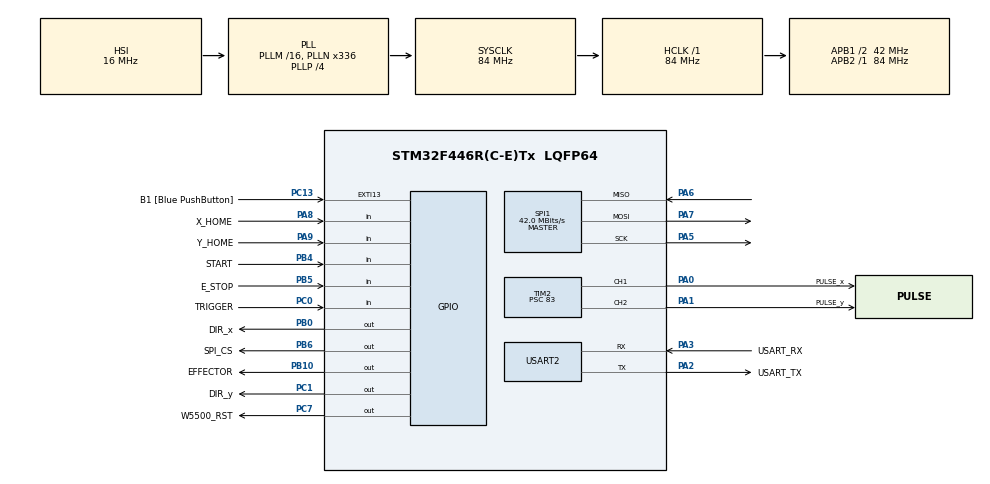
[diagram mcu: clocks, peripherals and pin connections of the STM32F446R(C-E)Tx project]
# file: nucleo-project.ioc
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Mcu.Family=STM32F4
Mcu.Name=STM32F446R(C-E)Tx
Mcu.Package=LQFP64
NVIC.PriorityGroup=NVIC_PRIORITYGROUP_4
NVIC.TIM2_IRQn=true\:0\:0\:false\:false\:true\:true\:true\:true
PA0-WKUP.GPIO_Label=PULSE_x
PA0-WKUP.GPIO_ModeDefaultPP=GPIO_MODE_AF_OD
PA0-WKUP.Signal=S_TIM2_CH1_ETR
PA1.GPIO_Label=PULSE_y
PA1.GPIO_ModeDefaultPP=GPIO_MODE_AF_OD
PA1.Signal=S_TIM2_CH2
PA13.GPIO_Label=TMS
PA13.Mode=Serial_Wire
PA13.Signal=SYS_JTMS-SWDIO
PA14.GPIO_Label=TCK
PA14.Mode=Serial_Wire
PA14.Signal=SYS_JTCK-SWCLK
PA2.GPIO_Label=USART_TX
PA2.Mode=Asynchronous
PA2.Signal=USART2_TX
PA3.GPIO_Label=USART_RX
PA3.Mode=Asynchronous
PA3.Signal=USART2_RX
PA5.Mode=Full_Duplex_Master
PA5.Signal=SPI1_SCK
PA6.Mode=Full_Duplex_Master
PA6.Signal=SPI1_MISO
PA7.Mode=Full_Duplex_Master
PA7.Signal=SPI1_MOSI
PA8.GPIO_Label=X_HOME
PA8.GPIO_PuPd=GPIO_PULLUP
PA8.Signal=GPIO_Input
PA9.GPIO_Label=Y_HOME
PA9.GPIO_PuPd=GPIO_PULLUP
PA9.Signal=GPIO_Input
PB0.GPIO_Label=DIR_x
PB0.GPIO_ModeDefaultOutputPP=GPIO_MODE_OUTPUT_OD
PB0.PinState=GPIO_PIN_SET
PB0.Signal=GPIO_Output
PB10.GPIO_Label=EFFECTOR
PB10.GPIO_ModeDefaultOutputPP=GPIO_MODE_OUTPUT_OD
PB10.GPIO_PuPd=GPIO_NOPULL
PB10.Signal=GPIO_Output
PB3.GPIO_Label=SWO
PB3.Signal=SYS_JTDO-SWO
PB4.GPIO_Label=START
PB4.GPIO_PuPd=GPIO_PULLUP
PB4.Signal=GPIO_Input
PB5.GPIO_Label=E_STOP
PB5.GPIO_PuPd=GPIO_PULLDOWN
PB5.Signal=GPIO_Input
PB6.GPIO_Label=SPI_CS
PB6.PinState=GPIO_PIN_SET
PB6.Signal=GPIO_Output
PC0.GPIO_Label=TRIGGER
PC0.GPIO_PuPd=GPIO_PULLUP
PC0.Signal=GPIO_Input
PC1.GPIO_Label=DIR_y
PC1.GPIO_ModeDefaultOutputPP=GPIO_MODE_OUTPUT_OD
PC1.PinState=GPIO_PIN_SET
PC1.Signal=GPIO_Output
PC13.GPIO_Label=B1 [Blue PushButton]
PC13.GPIO_ModeDefaultEXTI=GPIO_MODE_IT_FALLING
PC13.Signal=GPXTI13
PC14-OSC32_IN.Mode=LSE-External-Oscillator
PC14-OSC32_IN.Signal=RCC_OSC32_IN
PC15-OSC32_OUT.Mode=LSE-External-Oscillator
PC15-OSC32_OUT.Signal=RCC_OSC32_OUT
PC7.GPIO_Label=W5500_RST
PC7.PinState=GPIO_PIN_SET
PC7.Signal=GPIO_Output
PH0-OSC_IN.Mode=HSE-External-Oscillator
PH0-OSC_IN.Signal=RCC_OSC_IN
PH1-OSC_OUT.Mode=HSE-External-Oscillator
PH1-OSC_OUT.Signal=RCC_OSC_OUT
ProjectManager.HeapSize=0x200
ProjectManager.StackSize=0x400
ProjectManager.TargetToolchain=CMake
RCC.48MHZClocksFreq_Value=84000000
RCC.AHBFreq_Value=84000000
RCC.APB1CLKDivider=RCC_HCLK_DIV2
RCC.APB1Freq_Value=42000000
RCC.APB1TimFreq_Value=84000000
RCC.APB2Freq_Value=84000000
RCC.APB2TimFreq_Value=84000000
RCC.CortexFreq_Value=84000000
RCC.FLatency-AdvancedSettings=FLASH_LATENCY_2
RCC.HCLKFreq_Value=84000000
RCC.HSE_VALUE=8000000
RCC.HSI_VALUE=16000000
RCC.PLLN=336
RCC.PLLP=RCC_PLLP_DIV4
RCC.SYSCLKFreq_VALUE=84000000
RCC.SYSCLKSource=RCC_SYSCLKSOURCE_PLLCLK
RCC.USBFreq_Value=168000000
RCC.VCOOutputFreq_Value=336000000
SH.S_TIM2_CH1_ETR.0=TIM2_CH1,Output Compare1 CH1
SH.S_TIM2_CH2.0=TIM2_CH2,Output Compare2 CH2
SPI1.BaudRatePrescaler=SPI_BAUDRATEPRESCALER_2
SPI1.CLKPolarity=SPI_POLARITY_LOW
SPI1.CalculateBaudRate=42.0 MBits/s
SPI1.Direction=SPI_DIRECTION_2LINES
SPI1.Mode=SPI_MODE_MASTER
SPI1.VirtualType=VM_MASTER
TIM2.Channel-Output\ Compare1\ CH1=TIM_CHANNEL_1
TIM2.Channel-Output\ Compare2\ CH2=TIM_CHANNEL_2
TIM2.OCMode_1=TIM_OCMODE_TOGGLE
TIM2.OCMode_2=TIM_OCMODE_TOGGLE
TIM2.OCPolarity_1=TIM_OCPOLARITY_LOW
TIM2.OCPolarity_2=TIM_OCPOLARITY_LOW
TIM2.Prescaler=83
USART2.VirtualMode=VM_ASYNC
VP_TIM2_VS_ClockSourceINT.Mode=Internal
board=NUCLEO-F446RE

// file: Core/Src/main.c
/* USER CODE BEGIN Header */
/**
 ******************************************************************************
 * @file           : main.c
 * @brief          : Main program body
 ******************************************************************************
 * @attention
 *
 * Copyright (c) 2026 STMicroelectronics.
 * All rights reserved.
 *
 * This software is licensed under terms that can be found in the LICENSE file
 * in the root directory of this software component.
 * If no LICENSE file comes with this software, it is provided AS-IS.
 *
 ******************************************************************************
 */
/* USER CODE END Header */
#include "main.h"

/* USER CODE BEGIN Includes */

#include "entrypoint.hpp"

#include "stm32f4xx_hal.h"
#include "stm32f4xx_hal_def.h"
#include "stm32f4xx_hal_uart.h"

#include <stdint.h>

/* USER CODE END Includes */

SPI_HandleTypeDef hspi1;

TIM_HandleTypeDef htim2;

UART_HandleTypeDef huart2;

void SystemClock_Config(void);
static void MX_GPIO_Init(void);
static void MX_USART2_UART_Init(void);
static void MX_SPI1_Init(void);
static void MX_TIM2_Init(void);

/* USER CODE BEGIN 0 */

int __io_putchar(int ch)
{
    HAL_UART_Transmit(&huart2, (uint8_t *)&ch, 1, HAL_MAX_DELAY);
    return ch;
}

/* USER CODE END 0 */

int main(void)
{

  /* MCU Configuration--------------------------------------------------------*/

  /* Reset of all peripherals, Initializes the Flash interface and the Systick. */
  HAL_Init();

  /* Configure the system clock */
  SystemClock_Config();

  /* Initialize all configured peripherals */
  MX_GPIO_Init();
  MX_USART2_UART_Init();
  MX_SPI1_Init();
  MX_TIM2_Init();
  /* USER CODE BEGIN 2 */

    setup();

  /* USER CODE END 2 */

  /* Infinite loop */
  /* USER CODE BEGIN WHILE */

    while (1)
    {
        loop();

    /* USER CODE END WHILE */

    }
}

void SystemClock_Config(void)
{
  RCC_OscInitTypeDef RCC_OscInitStruct = {0};
  RCC_ClkInitTypeDef RCC_ClkInitStruct = {0};

  /** Configure the main internal regulator output voltage
  */
  __HAL_RCC_PWR_CLK_ENABLE();
  __HAL_PWR_VOLTAGESCALING_CONFIG(PWR_REGULATOR_VOLTAGE_SCALE3);

  /** Initializes the RCC Oscillators according to the specified parameters
  * in the RCC_OscInitTypeDef structure.
  */
  RCC_OscInitStruct.OscillatorType = RCC_OSCILLATORTYPE_HSI;
  RCC_OscInitStruct.HSIState = RCC_HSI_ON;
  RCC_OscInitStruct.HSICalibrationValue = RCC_HSICALIBRATION_DEFAULT;
  RCC_OscInitStruct.PLL.PLLState = RCC_PLL_ON;
  RCC_OscInitStruct.PLL.PLLSource = RCC_PLLSOURCE_HSI;
  RCC_OscInitStruct.PLL.PLLM = 16;
  RCC_OscInitStruct.PLL.PLLN = 336;
  RCC_OscInitStruct.PLL.PLLP = RCC_PLLP_DIV4;
  RCC_OscInitStruct.PLL.PLLQ = 2;
  RCC_OscInitStruct.PLL.PLLR = 2;
  if (HAL_RCC_OscConfig(&RCC_OscInitStruct) != HAL_OK)
  {
    Error_Handler();
  }

  /** Initializes the CPU, AHB and APB buses clocks
  */
  RCC_ClkInitStruct.ClockType = RCC_CLOCKTYPE_HCLK|RCC_CLOCKTYPE_SYSCLK
                              |RCC_CLOCKTYPE_PCLK1|RCC_CLOCKTYPE_PCLK2;
  RCC_ClkInitStruct.SYSCLKSource = RCC_SYSCLKSOURCE_PLLCLK;
  RCC_ClkInitStruct.AHBCLKDivider = RCC_SYSCLK_DIV1;
  RCC_ClkInitStruct.APB1CLKDivider = RCC_HCLK_DIV2;
  RCC_ClkInitStruct.APB2CLKDivider = RCC_HCLK_DIV1;

  if (HAL_RCC_ClockConfig(&RCC_ClkInitStruct, FLASH_LATENCY_2) != HAL_OK)
  {
    Error_Handler();
  }
}

static void MX_SPI1_Init(void)
{

  /* SPI1 parameter configuration*/
  hspi1.Instance = SPI1;
  hspi1.Init.Mode = SPI_MODE_MASTER;
  hspi1.Init.Direction = SPI_DIRECTION_2LINES;
  hspi1.Init.DataSize = SPI_DATASIZE_8BIT;
  hspi1.Init.CLKPolarity = SPI_POLARITY_LOW;
  hspi1.Init.CLKPhase = SPI_PHASE_1EDGE;
  hspi1.Init.NSS = SPI_NSS_SOFT;
  hspi1.Init.BaudRatePrescaler = SPI_BAUDRATEPRESCALER_2;
  hspi1.Init.FirstBit = SPI_FIRSTBIT_MSB;
  hspi1.Init.TIMode = SPI_TIMODE_DISABLE;
  hspi1.Init.CRCCalculation = SPI_CRCCALCULATION_DISABLE;
  hspi1.Init.CRCPolynomial = 10;
  if (HAL_SPI_Init(&hspi1) != HAL_OK)
  {
    Error_Handler();
  }

}

static void MX_TIM2_Init(void)
{

  TIM_ClockConfigTypeDef sClockSourceConfig = {0};
  TIM_MasterConfigTypeDef sMasterConfig = {0};
  TIM_OC_InitTypeDef sConfigOC = {0};

  htim2.Instance = TIM2;
  htim2.Init.Prescaler = 83;
  htim2.Init.CounterMode = TIM_COUNTERMODE_UP;
  htim2.Init.Period = 4294967295;
  htim2.Init.ClockDivision = TIM_CLOCKDIVISION_DIV1;
  htim2.Init.AutoReloadPreload = TIM_AUTORELOAD_PRELOAD_DISABLE;
  if (HAL_TIM_Base_Init(&htim2) != HAL_OK)
  {
    Error_Handler();
  }
  sClockSourceConfig.ClockSource = TIM_CLOCKSOURCE_INTERNAL;
  if (HAL_TIM_ConfigClockSource(&htim2, &sClockSourceConfig) != HAL_OK)
  {
    Error_Handler();
  }
  if (HAL_TIM_OC_Init(&htim2) != HAL_OK)
  {
    Error_Handler();
  }
  sMasterConfig.MasterOutputTrigger = TIM_TRGO_RESET;
  sMasterConfig.MasterSlaveMode = TIM_MASTERSLAVEMODE_DISABLE;
  if (HAL_TIMEx_MasterConfigSynchronization(&htim2, &sMasterConfig) != HAL_OK)
  {
    Error_Handler();
  }
  sConfigOC.OCMode = TIM_OCMODE_TOGGLE;
  sConfigOC.Pulse = 0;
  sConfigOC.OCPolarity = TIM_OCPOLARITY_LOW;
  sConfigOC.OCFastMode = TIM_OCFAST_DISABLE;
  if (HAL_TIM_OC_ConfigChannel(&htim2, &sConfigOC, TIM_CHANNEL_1) != HAL_OK)
  {
    Error_Handler();
  }
  if (HAL_TIM_OC_ConfigChannel(&htim2, &sConfigOC, TIM_CHANNEL_2) != HAL_OK)
  {
    Error_Handler();
  }
  HAL_TIM_MspPostInit(&htim2);

}

static void MX_USART2_UART_Init(void)
{

  huart2.Instance = USART2;
  huart2.Init.BaudRate = 115200;
  huart2.Init.WordLength = UART_WORDLENGTH_8B;
  huart2.Init.StopBits = UART_STOPBITS_1;
  huart2.Init.Parity = UART_PARITY_NONE;
  huart2.Init.Mode = UART_MODE_TX_RX;
  huart2.Init.HwFlowCtl = UART_HWCONTROL_NONE;
  huart2.Init.OverSampling = UART_OVERSAMPLING_16;
  if (HAL_UART_Init(&huart2) != HAL_OK)
  {
    Error_Handler();
  }

}

static void MX_GPIO_Init(void)
{
  GPIO_InitTypeDef GPIO_InitStruct = {0};

  /* GPIO Ports Clock Enable */
  __HAL_RCC_GPIOC_CLK_ENABLE();
  __HAL_RCC_GPIOH_CLK_ENABLE();
  __HAL_RCC_GPIOA_CLK_ENABLE();
  __HAL_RCC_GPIOB_CLK_ENABLE();
  __HAL_RCC_GPIOD_CLK_ENABLE();

  /*Configure GPIO pin Output Level */
  HAL_GPIO_WritePin(GPIOC, DIR_y_Pin|W5500_RST_Pin, GPIO_PIN_SET);

  /*Configure GPIO pin Output Level */
  HAL_GPIO_WritePin(GPIOB, DIR_x_Pin|SPI_CS_Pin, GPIO_PIN_SET);

  /*Configure GPIO pin Output Level */
  HAL_GPIO_WritePin(EFFECTOR_GPIO_Port, EFFECTOR_Pin, GPIO_PIN_RESET);

  /*Configure GPIO pin : B1_Pin */
  GPIO_InitStruct.Pin = B1_Pin;
  GPIO_InitStruct.Mode = GPIO_MODE_IT_FALLING;
  GPIO_InitStruct.Pull = GPIO_NOPULL;
  HAL_GPIO_Init(B1_GPIO_Port, &GPIO_InitStruct);

  /*Configure GPIO pin : TRIGGER_Pin */
  GPIO_InitStruct.Pin = TRIGGER_Pin;
  GPIO_InitStruct.Mode = GPIO_MODE_INPUT;
  GPIO_InitStruct.Pull = GPIO_PULLUP;
  HAL_GPIO_Init(TRIGGER_GPIO_Port, &GPIO_InitStruct);

  /*Configure GPIO pin : DIR_y_Pin */
  GPIO_InitStruct.Pin = DIR_y_Pin;
  GPIO_InitStruct.Mode = GPIO_MODE_OUTPUT_OD;
  GPIO_InitStruct.Pull = GPIO_NOPULL;
  GPIO_InitStruct.Speed = GPIO_SPEED_FREQ_LOW;
  HAL_GPIO_Init(DIR_y_GPIO_Port, &GPIO_InitStruct);

  /*Configure GPIO pins : PC2 PC3 PC4 PC5
                           PC6 PC8 PC9 PC10
                           PC11 PC12 */
  GPIO_InitStruct.Pin = GPIO_PIN_2|GPIO_PIN_3|GPIO_PIN_4|GPIO_PIN_5
                          |GPIO_PIN_6|GPIO_PIN_8|GPIO_PIN_9|GPIO_PIN_10
                          |GPIO_PIN_11|GPIO_PIN_12;
  GPIO_InitStruct.Mode = GPIO_MODE_ANALOG;
  GPIO_InitStruct.Pull = GPIO_NOPULL;
  HAL_GPIO_Init(GPIOC, &GPIO_InitStruct);

  /*Configure GPIO pins : PA4 PA10 PA11 PA12
                           PA15 */
  GPIO_InitStruct.Pin = GPIO_PIN_4|GPIO_PIN_10|GPIO_PIN_11|GPIO_PIN_12
                          |GPIO_PIN_15;
  GPIO_InitStruct.Mode = GPIO_MODE_ANALOG;
  GPIO_InitStruct.Pull = GPIO_NOPULL;
  HAL_GPIO_Init(GPIOA, &GPIO_InitStruct);

  /*Configure GPIO pins : DIR_x_Pin EFFECTOR_Pin */
  GPIO_InitStruct.Pin = DIR_x_Pin|EFFECTOR_Pin;
  GPIO_InitStruct.Mode = GPIO_MODE_OUTPUT_OD;
  GPIO_InitStruct.Pull = GPIO_NOPULL;
  GPIO_InitStruct.Speed = GPIO_SPEED_FREQ_LOW;
  HAL_GPIO_Init(GPIOB, &GPIO_InitStruct);

  /*Configure GPIO pins : PB1 PB2 PB12 PB13
                           PB14 PB15 PB7 PB8
                           PB9 */
  GPIO_InitStruct.Pin = GPIO_PIN_1|GPIO_PIN_2|GPIO_PIN_12|GPIO_PIN_13
                          |GPIO_PIN_14|GPIO_PIN_15|GPIO_PIN_7|GPIO_PIN_8
                          |GPIO_PIN_9;
  GPIO_InitStruct.Mode = GPIO_MODE_ANALOG;
  GPIO_InitStruct.Pull = GPIO_NOPULL;
  HAL_GPIO_Init(GPIOB, &GPIO_InitStruct);

  /*Configure GPIO pin : W5500_RST_Pin */
  GPIO_InitStruct.Pin = W5500_RST_Pin;
  GPIO_InitStruct.Mode = GPIO_MODE_OUTPUT_PP;
  GPIO_InitStruct.Pull = GPIO_NOPULL;
  GPIO_InitStruct.Speed = GPIO_SPEED_FREQ_LOW;
  HAL_GPIO_Init(W5500_RST_GPIO_Port, &GPIO_InitStruct);

  /*Configure GPIO pins : X_HOME_Pin Y_HOME_Pin */
  GPIO_InitStruct.Pin = X_HOME_Pin|Y_HOME_Pin;
  GPIO_InitStruct.Mode = GPIO_MODE_INPUT;
  GPIO_InitStruct.Pull = GPIO_PULLUP;
  HAL_GPIO_Init(GPIOA, &GPIO_InitStruct);

  /*Configure GPIO pin : PD2 */
  GPIO_InitStruct.Pin = GPIO_PIN_2;
  GPIO_InitStruct.Mode = GPIO_MODE_ANALOG;
  GPIO_InitStruct.Pull = GPIO_NOPULL;
  HAL_GPIO_Init(GPIOD, &GPIO_InitStruct);

  /*Configure GPIO pin : START_Pin */
  GPIO_InitStruct.Pin = START_Pin;
  GPIO_InitStruct.Mode = GPIO_MODE_INPUT;
  GPIO_InitStruct.Pull = GPIO_PULLUP;
  HAL_GPIO_Init(START_GPIO_Port, &GPIO_InitStruct);

  /*Configure GPIO pin : E_STOP_Pin */
  GPIO_InitStruct.Pin = E_STOP_Pin;
  GPIO_InitStruct.Mode = GPIO_MODE_INPUT;
  GPIO_InitStruct.Pull = GPIO_PULLDOWN;
  HAL_GPIO_Init(E_STOP_GPIO_Port, &GPIO_InitStruct);

  /*Configure GPIO pin : SPI_CS_Pin */
  GPIO_InitStruct.Pin = SPI_CS_Pin;
  GPIO_InitStruct.Mode = GPIO_MODE_OUTPUT_PP;
  GPIO_InitStruct.Pull = GPIO_NOPULL;
  GPIO_InitStruct.Speed = GPIO_SPEED_FREQ_LOW;
  HAL_GPIO_Init(SPI_CS_GPIO_Port, &GPIO_InitStruct);

}

void Error_Handler(void)
{
    __disable_irq();
    while (1)
    {
    }
}
